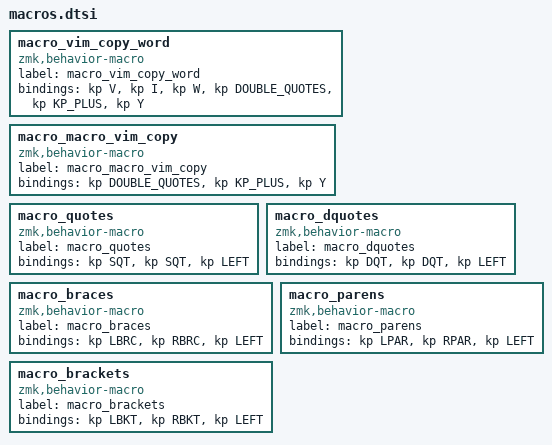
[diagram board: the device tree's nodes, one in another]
macro_vim_copy_word: macro_vim_copy_word{
compatible = "zmk,behavior-macro";
label = "macro_vim_copy_word";
#binding-cells = <0>;
bindings = <&kp V>, <&kp I>, <&kp W>, <&kp DOUBLE_QUOTES>, <&kp KP_PLUS>, <&kp Y>;
};
macro_macro_vim_copy: macro_macro_vim_copy{
compatible = "zmk,behavior-macro";
label = "macro_macro_vim_copy";
#binding-cells = <0>;
bindings = <&kp DOUBLE_QUOTES>, <&kp KP_PLUS>, <&kp Y>;
};
macro_quotes: macro_quotes{
compatible = "zmk,behavior-macro";
label = "macro_quotes";
#binding-cells = <0>;
bindings = <&kp SQT>, <&kp SQT>, <&kp LEFT>;
};
macro_dquotes: macro_dquotes{
compatible = "zmk,behavior-macro";
label = "macro_dquotes";
#binding-cells = <0>;
bindings = <&kp DQT>, <&kp DQT>, <&kp LEFT>;
};
macro_braces: macro_braces{
compatible = "zmk,behavior-macro";
label = "macro_braces";
#binding-cells = <0>;
bindings = <&kp LBRC>, <&kp RBRC>, <&kp LEFT>;
};
macro_parens: macro_parens{
compatible = "zmk,behavior-macro";
label = "macro_parens";
#binding-cells = <0>;
bindings = <&kp LPAR>, <&kp RPAR>, <&kp LEFT>;
};
macro_brackets: macro_brackets{
compatible = "zmk,behavior-macro";
label = "macro_brackets";
#binding-cells = <0>;
bindings = <&kp LBKT>, <&kp RBKT>, <&kp LEFT>;
};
